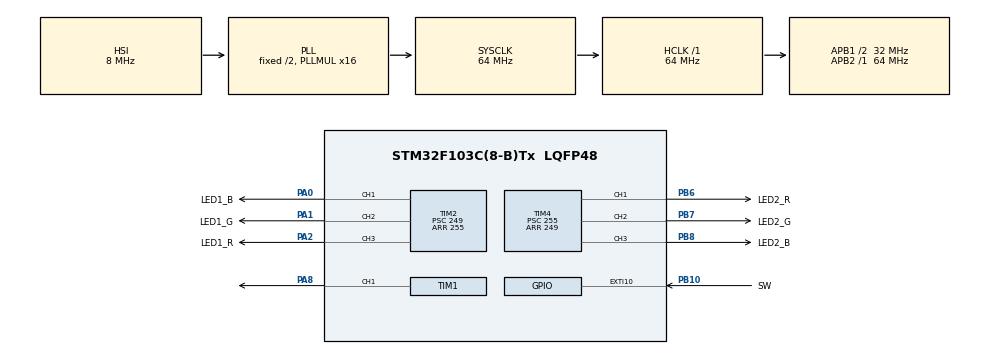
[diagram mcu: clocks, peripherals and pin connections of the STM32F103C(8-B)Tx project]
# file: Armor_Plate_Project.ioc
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Mcu.Family=STM32F1
Mcu.Name=STM32F103C(8-B)Tx
Mcu.Package=LQFP48
NVIC.EXTI15_10_IRQn=true\:10\:0\:true\:false\:true\:true\:true
NVIC.PriorityGroup=NVIC_PRIORITYGROUP_4
PA0-WKUP.GPIO_Label=LED1_B
PA0-WKUP.GPIO_Speed=GPIO_SPEED_FREQ_MEDIUM
PA0-WKUP.Signal=S_TIM2_CH1_ETR
PA1.GPIO_Label=LED1_G
PA1.GPIO_Speed=GPIO_SPEED_FREQ_MEDIUM
PA1.Signal=S_TIM2_CH2
PA13.Mode=Serial_Wire
PA13.Signal=SYS_JTMS-SWDIO
PA14.Mode=Serial_Wire
PA14.Signal=SYS_JTCK-SWCLK
PA2.GPIO_Label=LED1_R
PA2.GPIO_Speed=GPIO_SPEED_FREQ_MEDIUM
PA2.Signal=S_TIM2_CH3
PA8.GPIO_Speed=GPIO_SPEED_FREQ_LOW
PA8.Signal=S_TIM1_CH1
PB10.GPIO_Label=SW
PB10.GPIO_PuPd=GPIO_PULLUP
PB10.Signal=GPXTI10
PB6.GPIO_Label=LED2_R
PB6.GPIO_Speed=GPIO_SPEED_FREQ_MEDIUM
PB6.Signal=S_TIM4_CH1
PB7.GPIO_Label=LED2_G
PB7.GPIO_Speed=GPIO_SPEED_FREQ_MEDIUM
PB7.Signal=S_TIM4_CH2
PB8.GPIO_Label=LED2_B
PB8.GPIO_Speed=GPIO_SPEED_FREQ_MEDIUM
PB8.Signal=S_TIM4_CH3
ProjectManager.HeapSize=0x200
ProjectManager.StackSize=0x400
ProjectManager.TargetToolchain=STM32CubeIDE
RCC.AHBFreq_Value=64000000
RCC.APB1CLKDivider=RCC_HCLK_DIV2
RCC.APB1Freq_Value=32000000
RCC.APB1TimFreq_Value=64000000
RCC.APB2Freq_Value=64000000
RCC.APB2TimFreq_Value=64000000
RCC.HCLKFreq_Value=64000000
RCC.PLLMUL=RCC_PLL_MUL16
RCC.SYSCLKFreq_VALUE=64000000
RCC.SYSCLKSource=RCC_SYSCLKSOURCE_PLLCLK
RCC.USBFreq_Value=64000000
SH.S_TIM1_CH1.0=TIM1_CH1,PWM Generation1 CH1
SH.S_TIM2_CH1_ETR.0=TIM2_CH1,PWM Generation1 CH1
SH.S_TIM2_CH2.0=TIM2_CH2,PWM Generation2 CH2
SH.S_TIM2_CH3.0=TIM2_CH3,PWM Generation3 CH3
SH.S_TIM4_CH1.0=TIM4_CH1,PWM Generation1 CH1
SH.S_TIM4_CH2.0=TIM4_CH2,PWM Generation2 CH2
SH.S_TIM4_CH3.0=TIM4_CH3,PWM Generation3 CH3
TIM1.Channel-PWM\ Generation1\ CH1=TIM_CHANNEL_1
TIM2.Channel-PWM\ Generation1\ CH1=TIM_CHANNEL_1
TIM2.Channel-PWM\ Generation2\ CH2=TIM_CHANNEL_2
TIM2.Channel-PWM\ Generation3\ CH3=TIM_CHANNEL_3
TIM2.Period=255
TIM2.Prescaler=249
TIM4.Channel-PWM\ Generation1\ CH1=TIM_CHANNEL_1
TIM4.Channel-PWM\ Generation2\ CH2=TIM_CHANNEL_2
TIM4.Channel-PWM\ Generation3\ CH3=TIM_CHANNEL_3
TIM4.Period=249
TIM4.Prescaler=255
board=custom

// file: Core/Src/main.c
/* USER CODE BEGIN Header */
/**
  ******************************************************************************
  * @file           : main.c
  * @brief          : Main program body
  * @author 		: Haoran
  ******************************************************************************
  * @attention
  *
  * Copyright (c) 2023 STMicroelectronics.
  * All rights reserved.
  *
  * This software is licensed under terms that can be found in the LICENSE file
  * in the root directory of this software component.
  *
  * @ project information
  * 	Brief: Use separated STM32 chip to develop a hand-held armor plate for
  * 		   testing auto aiming easily, without relying on referee systems.
  * 	Chip: STM32F103C8T6 minimum system board
  *
  *
  ******************************************************************************
  */
/* USER CODE END Header */
#include "main.h"

/* USER CODE BEGIN Includes */
#include "led.h"
/* USER CODE END Includes */

TIM_HandleTypeDef htim1;
TIM_HandleTypeDef htim2;
TIM_HandleTypeDef htim4;

void SystemClock_Config(void);
static void MX_GPIO_Init(void);
static void MX_TIM1_Init(void);
static void MX_TIM2_Init(void);
static void MX_TIM4_Init(void);

/* USER CODE BEGIN 0 */
LED_Color led_color;
/* USER CODE END 0 */

int main(void)
{

  /* MCU Configuration--------------------------------------------------------*/

  /* Reset of all peripherals, Initializes the Flash interface and the Systick. */
  HAL_Init();

  /* Configure the system clock */
  SystemClock_Config();

  /* Initialize all configured peripherals */
  MX_GPIO_Init();
  MX_TIM1_Init();
  MX_TIM2_Init();
  MX_TIM4_Init();
  /* USER CODE BEGIN 2 */
  led_init();
  /* default led color is blue */
  led_color = BLUE;
  /* USER CODE END 2 */

  /* Infinite loop */
  while (1)
  {

    /* USER CODE BEGIN 3 */
	  if(HAL_GPIO_ReadPin(SW_GPIO_Port, SW_Pin) == GPIO_PIN_SET)
		  led_color = RED;
	  else
		  led_color = BLUE;
	  /* select color */
	  if(led_color == BLUE)
		  led_set_color(0, 0, 255);
	  else if(led_color == RED)
		  led_set_color(255, 0, 0);
  }
  /* USER CODE END 3 */
}

void SystemClock_Config(void)
{
  RCC_OscInitTypeDef RCC_OscInitStruct = {0};
  RCC_ClkInitTypeDef RCC_ClkInitStruct = {0};

  /** Initializes the RCC Oscillators according to the specified parameters
  * in the RCC_OscInitTypeDef structure.
  */
  RCC_OscInitStruct.OscillatorType = RCC_OSCILLATORTYPE_HSI;
  RCC_OscInitStruct.HSIState = RCC_HSI_ON;
  RCC_OscInitStruct.HSICalibrationValue = RCC_HSICALIBRATION_DEFAULT;
  RCC_OscInitStruct.PLL.PLLState = RCC_PLL_ON;
  RCC_OscInitStruct.PLL.PLLSource = RCC_PLLSOURCE_HSI_DIV2;
  RCC_OscInitStruct.PLL.PLLMUL = RCC_PLL_MUL16;
  if (HAL_RCC_OscConfig(&RCC_OscInitStruct) != HAL_OK)
  {
    Error_Handler();
  }
  /** Initializes the CPU, AHB and APB buses clocks
  */
  RCC_ClkInitStruct.ClockType = RCC_CLOCKTYPE_HCLK|RCC_CLOCKTYPE_SYSCLK
                              |RCC_CLOCKTYPE_PCLK1|RCC_CLOCKTYPE_PCLK2;
  RCC_ClkInitStruct.SYSCLKSource = RCC_SYSCLKSOURCE_PLLCLK;
  RCC_ClkInitStruct.AHBCLKDivider = RCC_SYSCLK_DIV1;
  RCC_ClkInitStruct.APB1CLKDivider = RCC_HCLK_DIV2;
  RCC_ClkInitStruct.APB2CLKDivider = RCC_HCLK_DIV1;

  if (HAL_RCC_ClockConfig(&RCC_ClkInitStruct, FLASH_LATENCY_2) != HAL_OK)
  {
    Error_Handler();
  }
}

static void MX_TIM1_Init(void)
{

  TIM_MasterConfigTypeDef sMasterConfig = {0};
  TIM_OC_InitTypeDef sConfigOC = {0};
  TIM_BreakDeadTimeConfigTypeDef sBreakDeadTimeConfig = {0};

  htim1.Instance = TIM1;
  htim1.Init.Prescaler = 0;
  htim1.Init.CounterMode = TIM_COUNTERMODE_UP;
  htim1.Init.Period = 65535;
  htim1.Init.ClockDivision = TIM_CLOCKDIVISION_DIV1;
  htim1.Init.RepetitionCounter = 0;
  htim1.Init.AutoReloadPreload = TIM_AUTORELOAD_PRELOAD_DISABLE;
  if (HAL_TIM_PWM_Init(&htim1) != HAL_OK)
  {
    Error_Handler();
  }
  sMasterConfig.MasterOutputTrigger = TIM_TRGO_RESET;
  sMasterConfig.MasterSlaveMode = TIM_MASTERSLAVEMODE_DISABLE;
  if (HAL_TIMEx_MasterConfigSynchronization(&htim1, &sMasterConfig) != HAL_OK)
  {
    Error_Handler();
  }
  sConfigOC.OCMode = TIM_OCMODE_PWM1;
  sConfigOC.Pulse = 0;
  sConfigOC.OCPolarity = TIM_OCPOLARITY_HIGH;
  sConfigOC.OCNPolarity = TIM_OCNPOLARITY_HIGH;
  sConfigOC.OCFastMode = TIM_OCFAST_DISABLE;
  sConfigOC.OCIdleState = TIM_OCIDLESTATE_RESET;
  sConfigOC.OCNIdleState = TIM_OCNIDLESTATE_RESET;
  if (HAL_TIM_PWM_ConfigChannel(&htim1, &sConfigOC, TIM_CHANNEL_1) != HAL_OK)
  {
    Error_Handler();
  }
  sBreakDeadTimeConfig.OffStateRunMode = TIM_OSSR_DISABLE;
  sBreakDeadTimeConfig.OffStateIDLEMode = TIM_OSSI_DISABLE;
  sBreakDeadTimeConfig.LockLevel = TIM_LOCKLEVEL_OFF;
  sBreakDeadTimeConfig.DeadTime = 0;
  sBreakDeadTimeConfig.BreakState = TIM_BREAK_DISABLE;
  sBreakDeadTimeConfig.BreakPolarity = TIM_BREAKPOLARITY_HIGH;
  sBreakDeadTimeConfig.AutomaticOutput = TIM_AUTOMATICOUTPUT_DISABLE;
  if (HAL_TIMEx_ConfigBreakDeadTime(&htim1, &sBreakDeadTimeConfig) != HAL_OK)
  {
    Error_Handler();
  }
  HAL_TIM_MspPostInit(&htim1);

}

static void MX_TIM2_Init(void)
{

  TIM_MasterConfigTypeDef sMasterConfig = {0};
  TIM_OC_InitTypeDef sConfigOC = {0};

  htim2.Instance = TIM2;
  htim2.Init.Prescaler = 249;
  htim2.Init.CounterMode = TIM_COUNTERMODE_UP;
  htim2.Init.Period = 255;
  htim2.Init.ClockDivision = TIM_CLOCKDIVISION_DIV1;
  htim2.Init.AutoReloadPreload = TIM_AUTORELOAD_PRELOAD_DISABLE;
  if (HAL_TIM_PWM_Init(&htim2) != HAL_OK)
  {
    Error_Handler();
  }
  sMasterConfig.MasterOutputTrigger = TIM_TRGO_RESET;
  sMasterConfig.MasterSlaveMode = TIM_MASTERSLAVEMODE_DISABLE;
  if (HAL_TIMEx_MasterConfigSynchronization(&htim2, &sMasterConfig) != HAL_OK)
  {
    Error_Handler();
  }
  sConfigOC.OCMode = TIM_OCMODE_PWM1;
  sConfigOC.Pulse = 0;
  sConfigOC.OCPolarity = TIM_OCPOLARITY_HIGH;
  sConfigOC.OCFastMode = TIM_OCFAST_DISABLE;
  if (HAL_TIM_PWM_ConfigChannel(&htim2, &sConfigOC, TIM_CHANNEL_1) != HAL_OK)
  {
    Error_Handler();
  }
  if (HAL_TIM_PWM_ConfigChannel(&htim2, &sConfigOC, TIM_CHANNEL_2) != HAL_OK)
  {
    Error_Handler();
  }
  if (HAL_TIM_PWM_ConfigChannel(&htim2, &sConfigOC, TIM_CHANNEL_3) != HAL_OK)
  {
    Error_Handler();
  }
  HAL_TIM_MspPostInit(&htim2);

}

static void MX_TIM4_Init(void)
{

  TIM_MasterConfigTypeDef sMasterConfig = {0};
  TIM_OC_InitTypeDef sConfigOC = {0};

  htim4.Instance = TIM4;
  htim4.Init.Prescaler = 255;
  htim4.Init.CounterMode = TIM_COUNTERMODE_UP;
  htim4.Init.Period = 249;
  htim4.Init.ClockDivision = TIM_CLOCKDIVISION_DIV1;
  htim4.Init.AutoReloadPreload = TIM_AUTORELOAD_PRELOAD_DISABLE;
  if (HAL_TIM_PWM_Init(&htim4) != HAL_OK)
  {
    Error_Handler();
  }
  sMasterConfig.MasterOutputTrigger = TIM_TRGO_RESET;
  sMasterConfig.MasterSlaveMode = TIM_MASTERSLAVEMODE_DISABLE;
  if (HAL_TIMEx_MasterConfigSynchronization(&htim4, &sMasterConfig) != HAL_OK)
  {
    Error_Handler();
  }
  sConfigOC.OCMode = TIM_OCMODE_PWM1;
  sConfigOC.Pulse = 0;
  sConfigOC.OCPolarity = TIM_OCPOLARITY_HIGH;
  sConfigOC.OCFastMode = TIM_OCFAST_DISABLE;
  if (HAL_TIM_PWM_ConfigChannel(&htim4, &sConfigOC, TIM_CHANNEL_1) != HAL_OK)
  {
    Error_Handler();
  }
  if (HAL_TIM_PWM_ConfigChannel(&htim4, &sConfigOC, TIM_CHANNEL_2) != HAL_OK)
  {
    Error_Handler();
  }
  if (HAL_TIM_PWM_ConfigChannel(&htim4, &sConfigOC, TIM_CHANNEL_3) != HAL_OK)
  {
    Error_Handler();
  }
  HAL_TIM_MspPostInit(&htim4);

}

static void MX_GPIO_Init(void)
{
  GPIO_InitTypeDef GPIO_InitStruct = {0};

  /* GPIO Ports Clock Enable */
  __HAL_RCC_GPIOA_CLK_ENABLE();
  __HAL_RCC_GPIOB_CLK_ENABLE();

  /*Configure GPIO pin : SW_Pin */
  GPIO_InitStruct.Pin = SW_Pin;
  GPIO_InitStruct.Mode = GPIO_MODE_IT_RISING;
  GPIO_InitStruct.Pull = GPIO_PULLUP;
  HAL_GPIO_Init(SW_GPIO_Port, &GPIO_InitStruct);

  /* EXTI interrupt init*/
  HAL_NVIC_SetPriority(EXTI15_10_IRQn, 10, 0);
  HAL_NVIC_EnableIRQ(EXTI15_10_IRQn);

}

/* USER CODE BEGIN 4 */
//void HAL_GPIO_EXTI_Callback(uint16_t GPIO_Pin)
//{
//    if(GPIO_Pin == SW_Pin)
//    {
//    	HAL_Delay(100);
//    	if(GPIO_Pin == SW_Pin){
//    		if(led_color == BLUE)
//				led_color = RED;
//			else if(led_color == RED)
//				led_color = BLUE;
//    	}
//
//    }
//}
/* USER CODE END 4 */

void Error_Handler(void)
{
  __disable_irq();
  while (1)
  {
  }
}
